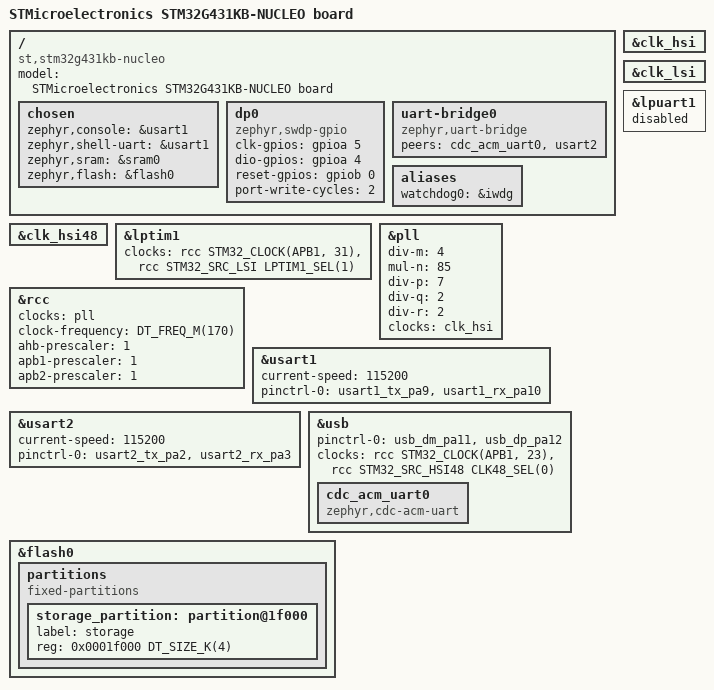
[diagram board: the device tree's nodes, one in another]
/*
 * Copyright (c) 2024 Klaus Nagel, <nagelkl01@gmail.com>
 *
 * SPDX-License-Identifier: Apache-2.0
 */

/dts-v1/;
#include <st/g4/stm32g431Xb.dtsi>
#include <st/g4/stm32g431k(6-8-b)tx-pinctrl.dtsi>

/ {
	model = "STMicroelectronics STM32G431KB-NUCLEO board";
	compatible = "st,stm32g431kb-nucleo";

	chosen {
		zephyr,console = &usart1;
		zephyr,shell-uart = &usart1;
		zephyr,sram = &sram0;
		zephyr,flash = &flash0;
	};

	dp0 {
		compatible = "zephyr,swdp-gpio";
	//        compatible = "arm,cmsis-dap";
		status = "okay";
		clk-gpios = <&gpioa 5 GPIO_ACTIVE_HIGH>;
		dio-gpios  = <&gpioa 4 GPIO_PULL_UP>;
		reset-gpios = <&gpiob 0 GPIO_ACTIVE_HIGH>;
		port-write-cycles = <2>;
	};

	uart-bridge0 {
		compatible = "zephyr,uart-bridge";
		peers = <&cdc_acm_uart0 &usart2>;
	};

	aliases {
		watchdog0 = &iwdg;
	};
};

&clk_hsi {
	status = "okay";
};

&clk_hsi48 {
    status = "okay";
};

&clk_lsi {
	status = "okay";
};


stm32_lp_tick_source: &lptim1 {
	clocks = <&rcc STM32_CLOCK(APB1, 31)>,
		 <&rcc STM32_SRC_LSI LPTIM1_SEL(1)>;
	status = "okay";
};

/* Adjust the pll for a SYSTEM Clock of 170MHz  */
&pll {
	div-m = <4>;
	mul-n = <85>;
	div-p = <7>;
	div-q = <2>;
	div-r = <2>;
	clocks = <&clk_hsi>;
	status = "okay";
};

&rcc {
	clocks = <&pll>;
	clock-frequency = <DT_FREQ_M(170)>;
	ahb-prescaler = <1>;
	apb1-prescaler = <1>;
	apb2-prescaler = <1>;
};

// &lpuart1 {
// 	pinctrl-0 = <&lpuart1_tx_pa2 &lpuart1_rx_pa3>;
// 	pinctrl-names = "default";
// 	current-speed = <115200>;
// 	status = "okay";
// };

&lpuart1 {
	status = "disabled";
};

&usart1 {
    status = "okay";
    current-speed = <115200>;
    pinctrl-0 = <&usart1_tx_pa9 &usart1_rx_pa10>;
    pinctrl-names = "default";
};

&usart2 {
    status = "okay";
    current-speed = <115200>;
    pinctrl-0 = <&usart2_tx_pa2 &usart2_rx_pa3>;
    pinctrl-names = "default";
};

// &i2c2 {
// 	pinctrl-0 = <&i2c2_scl_pa9 &i2c2_sda_pa8>;
// 	pinctrl-names = "default";
// 	status = "okay";
// };

zephyr_udc0: &usb {
    status = "okay";
    pinctrl-0 = <&usb_dm_pa11 &usb_dp_pa12>;
    pinctrl-names = "default";
    clocks = <&rcc STM32_CLOCK(APB1, 23)>,
		 <&rcc STM32_SRC_HSI48 CLK48_SEL(0)>;

    cdc_acm_uart0: cdc_acm_uart0 {
        compatible = "zephyr,cdc-acm-uart";
    };
};

&flash0 {
	partitions {
		compatible = "fixed-partitions";
		#address-cells = <1>;
		#size-cells = <1>;

		/* Set 4Kb of storage at the end of the 128Kb of flash */
		storage_partition: partition@1f000 {
			label = "storage";
			reg = <0x0001f000 DT_SIZE_K(4)>;
		};
	};
};
